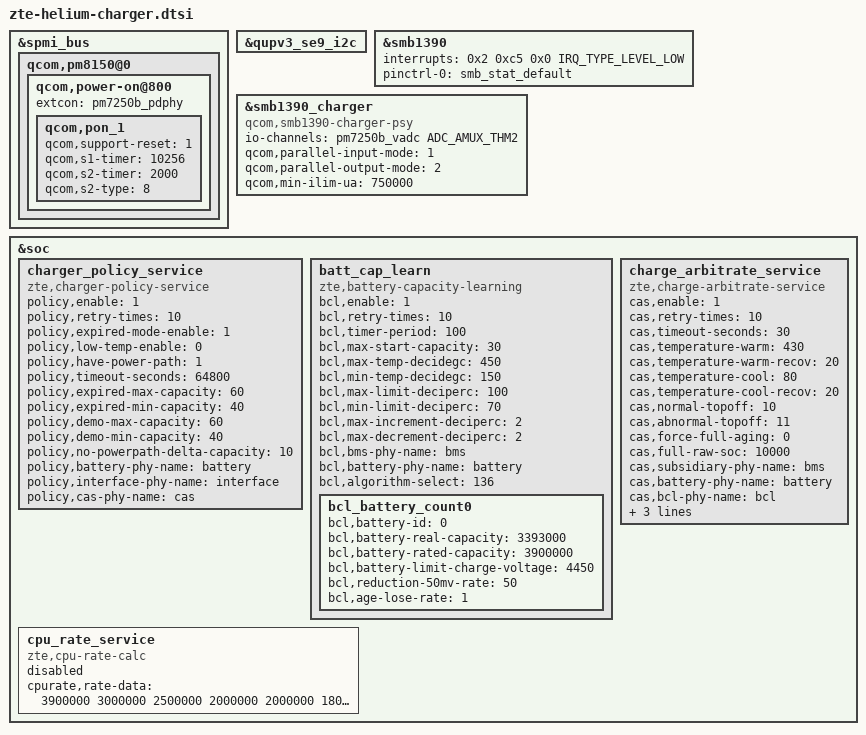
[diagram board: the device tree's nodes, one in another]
&spmi_bus {
	qcom,pm8150@0 {
		qcom,power-on@800 {
			extcon = <&pm7250b_pdphy>;
			qcom,pon_1 {
				qcom,support-reset = <1>;
				qcom,s1-timer = <10256>;
				qcom,s2-timer = <2000>;
				qcom,s2-type = <8>;
			};
		};
	};
};

&qupv3_se9_i2c {
	status = "ok";
	#include "smb1390.dtsi"
};

&smb1390 {
	/delete-property/ interrupts;
	interrupts = <0x2 0xc5 0x0 IRQ_TYPE_LEVEL_LOW>;
	pinctrl-names = "default";
	pinctrl-0 = <&smb_stat_default>;
	status = "ok";
};

&smb1390_charger {
	compatible = "qcom,smb1390-charger-psy";
	io-channels = <&pm7250b_vadc ADC_AMUX_THM2>;
	io-channel-names = "cp_die_temp";
	qcom,parallel-input-mode = <1>; /* USBIN */
	qcom,parallel-output-mode = <2>; /* VBAT */
	qcom,min-ilim-ua = <750000>;
	status = "ok";
};

&soc {
	charger_policy_service {
		compatible = "zte,charger-policy-service";
		status = "okay";
		policy,enable = <1>;
		policy,retry-times = <10>;
		policy,expired-mode-enable = <1>;
		policy,low-temp-enable = <0>;
		policy,have-power-path = <1>;
		policy,timeout-seconds = <64800>;
		policy,expired-max-capacity = <60>;
		policy,expired-min-capacity = <40>;
		policy,demo-max-capacity = <60>;
		policy,demo-min-capacity = <40>;
		policy,no-powerpath-delta-capacity = <10>;
		policy,battery-phy-name = "battery";
		policy,interface-phy-name = "interface";
		policy,cas-phy-name = "cas";
	};

	batt_cap_learn {
		compatible = "zte,battery-capacity-learning";
		bcl,enable = <1>;
		bcl,retry-times = <10>;
		bcl,timer-period = <100>;
		bcl,max-start-capacity = <30>;
		bcl,max-temp-decidegc = <450>;
		bcl,min-temp-decidegc = <150>;
		bcl,max-limit-deciperc = <100>;
		bcl,min-limit-deciperc = <70>;
		bcl,max-increment-deciperc = <2>;
		bcl,max-decrement-deciperc = <2>;
		bcl,bms-phy-name = "bms";
		bcl,battery-phy-name = "battery";
		bcl,algorithm-select = <136>;

		bcl_battery_count0 {
			bcl,battery-id = <0>;
			bcl,battery-real-capacity = <3393000>;
			bcl,battery-rated-capacity = <3900000>;
			bcl,battery-limit-charge-voltage = <4450>;
			bcl,reduction-50mv-rate = <50>;
			bcl,age-lose-rate = <1>;
		};
	};

	charge_arbitrate_service {
		compatible = "zte,charge-arbitrate-service";
		cas,enable = <1>;
		cas,retry-times = <10>;
		cas,timeout-seconds = <30>;
		cas,temperature-warm = <430>;
		cas,temperature-warm-recov = <20>;
		cas,temperature-cool = <80>;
		cas,temperature-cool-recov = <20>;
		cas,normal-topoff = <10>;
		cas,abnormal-topoff = <11>;
		cas,force-full-aging = <0>;
		cas,full-raw-soc = <10000>;
		cas,subsidiary-phy-name = "bms";
		cas,battery-phy-name = "battery";
		cas,bcl-phy-name = "bcl";
		cas,interface-phy-name = "interface";
		cas,age-data = <100 4450000 3900000 99 93 0 0
				95 4430000 3700000 98 92 0 0
				90 4410000 3500000 97 91 0 0
				85 4390000 3360000 96 90 0 0
				80 4370000 3180000 95 89 0 0
				75 4350000 2900000 94 88 0 0>;
	};

	cpu_rate_service {
		compatible = "zte,cpu-rate-calc";
		status = "disabled";
		cpurate,rate-data = <3900000 3000000 2500000 2000000 2000000
							1800000 1500000 1000000 600000 300000 300000>;
	};
};
